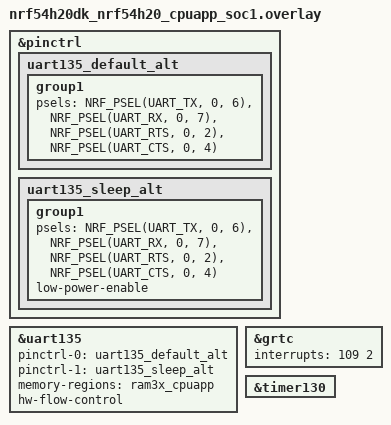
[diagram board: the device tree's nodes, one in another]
/* SPDX-License-Identifier: Apache-2.0 */

&pinctrl {
	uart135_default_alt: uart135_default_alt {
		group1 {
			psels = <NRF_PSEL(UART_TX, 0, 6)>,
				<NRF_PSEL(UART_RX, 0, 7)>,
				<NRF_PSEL(UART_RTS, 0, 2)>,
				<NRF_PSEL(UART_CTS, 0, 4)>;
		};
	};

	uart135_sleep_alt: uart135_sleep_alt {
		group1 {
			psels = <NRF_PSEL(UART_TX, 0, 6)>,
				<NRF_PSEL(UART_RX, 0, 7)>,
				<NRF_PSEL(UART_RTS, 0, 2)>,
				<NRF_PSEL(UART_CTS, 0, 4)>;
			low-power-enable;
		};
	};
};

dut: &uart135 {
	status = "okay";
	pinctrl-0 = <&uart135_default_alt>;
	pinctrl-1 = <&uart135_sleep_alt>;
	pinctrl-names = "default", "sleep";
	memory-regions = <&ram3x_cpuapp>;
	hw-flow-control;
};

&grtc {
	interrupts = <109 2>;
};

counter_dev: &timer130 {
	status = "okay";
};
